# SYS_INTC register map
Vendor: Texas Instruments
Peripheral module from a debugger description file (folder omap4430).
Registers are 32-bit, read-only, reset 0x0 unless marked. A register's access mark holds for its fields unless they carry their own. Offsets are as the file gives them; lines under a group give offsets from that group; [hi:lo] are bit positions; {n}, {i} and the like mark numbered series; 'fields as' and 'values as' point back to an identical list; <NAME> marks a mode.

## SYS_INTC
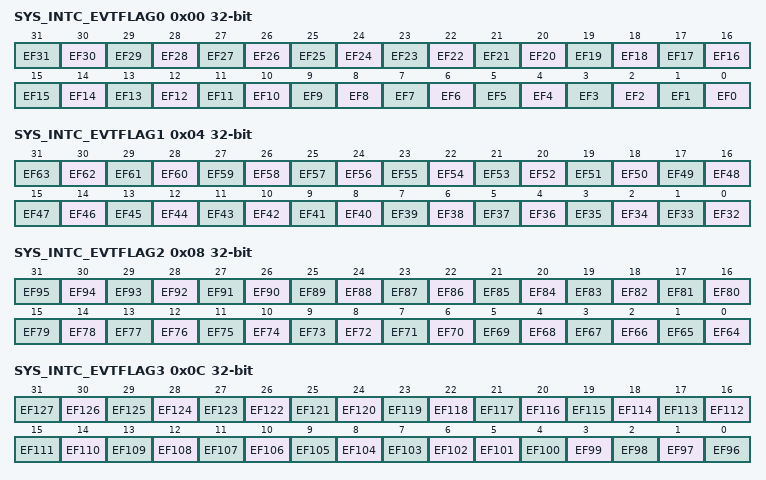
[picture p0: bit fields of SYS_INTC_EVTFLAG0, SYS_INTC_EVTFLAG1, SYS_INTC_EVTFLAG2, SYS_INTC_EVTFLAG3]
0x00 SYS_INTC_EVTFLAG0 — Event Flag Register 0
  [n] EF{n} (n=10..31) — Event Flag number {10n}: no event occurred1: an event occurred
  [n] EF{n} (n=0..9) — Event Flag number {10n:02}: no event occurred1: an event occurred
0x04 SYS_INTC_EVTFLAG1 — Event Flag Register 1
  [n-32] EF{n} (n=32..63) — Event Flag number {10n}: no event occurred1: an event occurred
0x08 SYS_INTC_EVTFLAG2 — Event Flag Register 2
  [n-64] EF{n} (n=64..95) — Event Flag number {10n}: no event occurred1: an event occurred
0x0C SYS_INTC_EVTFLAG3 — Event Flag Register 3
  [n-96] EF{n} (n=102..127) — Event Flag number {10n}: no event occurred1: an event occurred
  [5] EF101 — Event Flag number 1010: no event occurred 1: an event occurred
  [n-96] EF{n} (n=96..100) — Event Flag number {10n}: no event occurred1: an event occurred
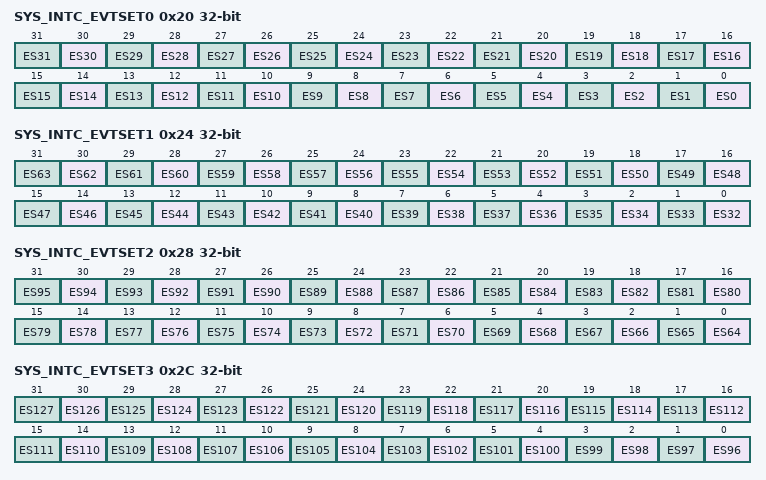
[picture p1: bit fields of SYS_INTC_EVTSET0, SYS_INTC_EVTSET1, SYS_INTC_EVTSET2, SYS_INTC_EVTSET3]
0x20 SYS_INTC_EVTSET0 wo — Event Set Register 0
  [n] ES{n} (n=0..31) — Event Set number {n}write 0: no actionwrite 1: set corresponding event flag
0x24 SYS_INTC_EVTSET1 wo — Event Set Register 1
  [n-32] ES{n} (n=32..63) — Event Set number {n}write 0: no actionwrite 1: set corresponding event flag
0x28 SYS_INTC_EVTSET2 wo — Event Set Register 2
  [n-64] ES{n} (n=64..95) — Event Set number {n}write 0: no actionwrite 1: set corresponding event flag
0x2C SYS_INTC_EVTSET3 wo — Event Set Register 3
  [n-96] ES{n} (n=96..127) — Event Set number {n}write 0: no actionwrite 1: set corresponding event flag
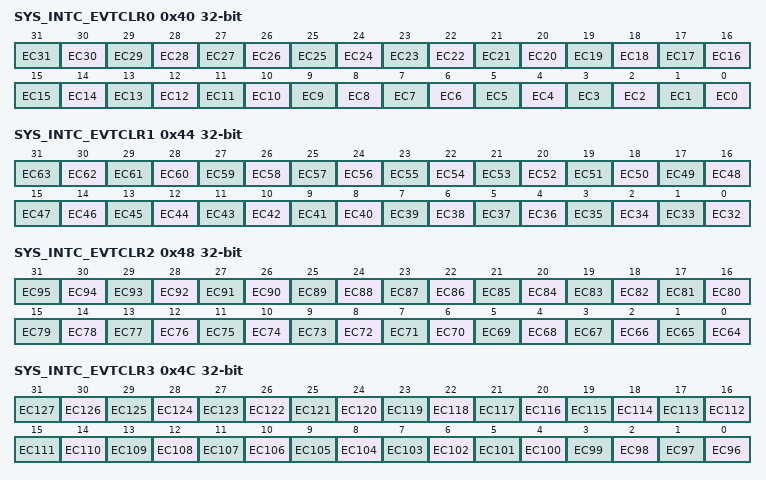
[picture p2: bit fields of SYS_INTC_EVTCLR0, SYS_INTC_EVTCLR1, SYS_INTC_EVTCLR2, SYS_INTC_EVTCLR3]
0x40 SYS_INTC_EVTCLR0 wo — Event Clear Register 0
  [n] EC{n} (n=0..31) — Event Clear number {n}write 0: no actionwrite 1: clear corresponding event
0x44 SYS_INTC_EVTCLR1 wo — Event Clear Register 1
  [n-32] EC{n} (n=32..63) — Event Clear number {n}write 0: no actionwrite 1: clear corresponding event
0x48 SYS_INTC_EVTCLR2 wo — Event Clear Register 2
  [n-64] EC{n} (n=64..95) — Event Clear number {n}write 0: no actionwrite 1: clear corresponding event
0x4C SYS_INTC_EVTCLR3 wo — Event Clear Register 3
  [n-96] EC{n} (n=96..127) — Event Clear number {n}write 0: no actionwrite 1: clear corresponding event
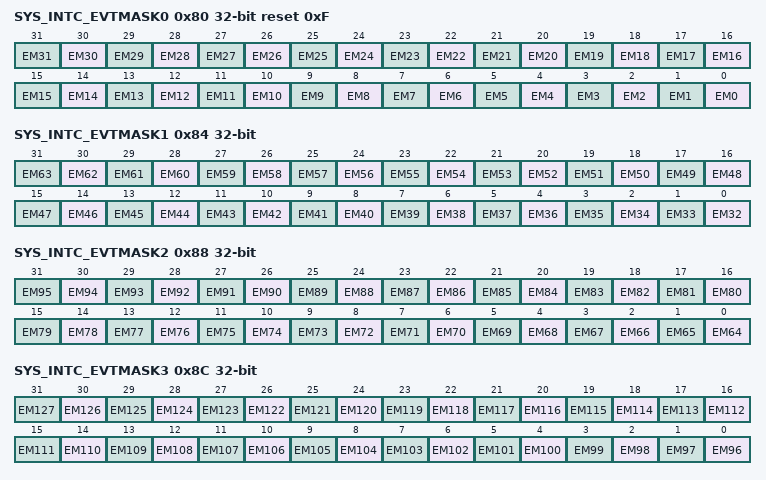
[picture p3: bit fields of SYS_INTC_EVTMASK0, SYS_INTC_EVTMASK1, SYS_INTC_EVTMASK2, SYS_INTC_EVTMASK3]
0x80 SYS_INTC_EVTMASK0 access per field reset 0xF — Event Mask Register 0
  [n] EM{n} rw (n=4..31) — Event Mask number {n}write 0: no actionwrite 1: mask corresponding event
  [n] EM{n} ro (n=0..3) — Event Mask number {n}write 0: no actionwrite 1: mask corresponding event
0x84 SYS_INTC_EVTMASK1 rw — Event Mask Register 1
  [n-32] EM{n} (n=32..63) — Event Mask number {n}write 0: no actionwrite 1: mask corresponding event
0x88 SYS_INTC_EVTMASK2 rw — Event Mask Register 2
  [n-64] EM{n} (n=64..95) — Event Mask number {n}write 0: no actionwrite 1: mask corresponding event
0x8C SYS_INTC_EVTMASK3 rw — Event Mask Register 3
  [n-96] EM{n} (n=100..127) — Event Mask number {n}write 0: no action write 1: mask corresponding event
  [n-96] EM{n} (n=96..99) — Event Mask number {n}write 0: no actionwrite 1: mask corresponding event
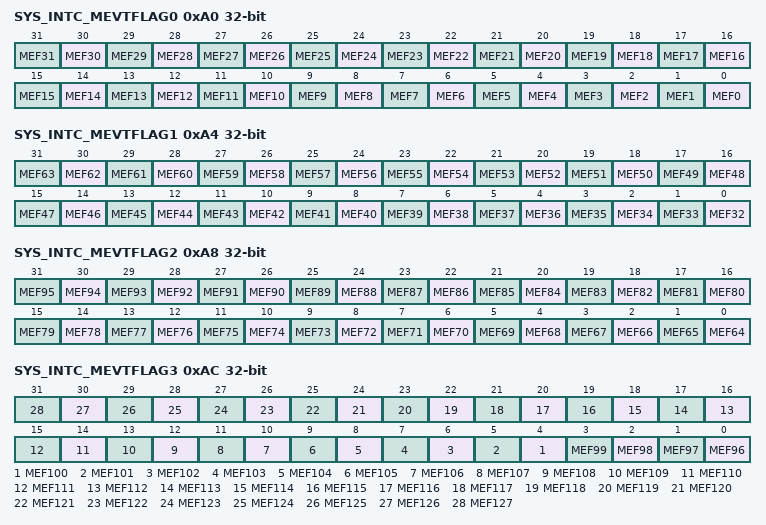
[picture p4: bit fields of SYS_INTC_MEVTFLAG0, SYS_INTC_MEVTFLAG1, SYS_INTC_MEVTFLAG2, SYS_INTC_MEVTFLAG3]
0xA0 SYS_INTC_MEVTFLAG0 — Masked Event Flag Register 0
  [n] MEF{n} (n=10..31) — Masked Event Flag number {10n}: no event occurred1: an event occurred
  [n] MEF{n} (n=0..9) — Masked Event Flag number {10n:02}: no event occurred1: an event occurred
0xA4 SYS_INTC_MEVTFLAG1 — Masked Event Flag Register 1
  [n-32] MEF{n} (n=32..63) — Masked Event Flag number {10n}: no event occurred1: an event occurred
0xA8 SYS_INTC_MEVTFLAG2 — Masked Event Flag Register 2
  [n-64] MEF{n} (n=64..95) — Masked Event Flag number {10n}: no event occurred1: an event occurred
0xAC SYS_INTC_MEVTFLAG3 — Masked Event Flag Register 3
  [n-96] MEF{n} (n=96..127) — Masked Event Flag number {10n}: no event occurred1: an event occurred
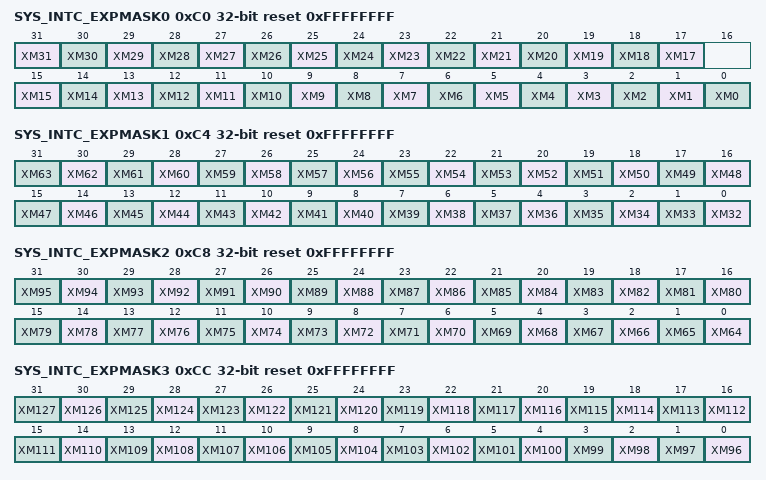
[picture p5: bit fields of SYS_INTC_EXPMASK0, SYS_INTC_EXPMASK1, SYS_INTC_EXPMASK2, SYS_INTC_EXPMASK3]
0xC0 SYS_INTC_EXPMASK0 access per field reset 0xFFFFFFFF — Exception Mask Register 0
  [n] XM{n} rw (n=17..31) — Exception Mask number {n}write 0: no action write 1: mask corresponding event
  [n] XM{n} rw (n=4..15) — Exception Mask number {n}write 0: no action write 1: mask corresponding event
  [n] XM{n} ro (n=0..3) — Exception Mask number {n}write 0: no action write 1: mask corresponding event
0xC4 SYS_INTC_EXPMASK1 rw reset 0xFFFFFFFF — Exception Mask Register 1
  [n-32] XM{n} (n=32..63) — Exception Mask number {n}write 0: no action write 1: mask corresponding event
0xC8 SYS_INTC_EXPMASK2 rw reset 0xFFFFFFFF — Exception Mask Register 2
  [n-64] XM{n} (n=64..95) — Exception Mask number {n}write 0: no action write 1: mask corresponding event
0xCC SYS_INTC_EXPMASK3 rw reset 0xFFFFFFFF — Exception Mask Register 3
  [n-96] XM{n} (n=96..127) — Exception Mask number {n}write 0: no action write 1: mask corresponding event
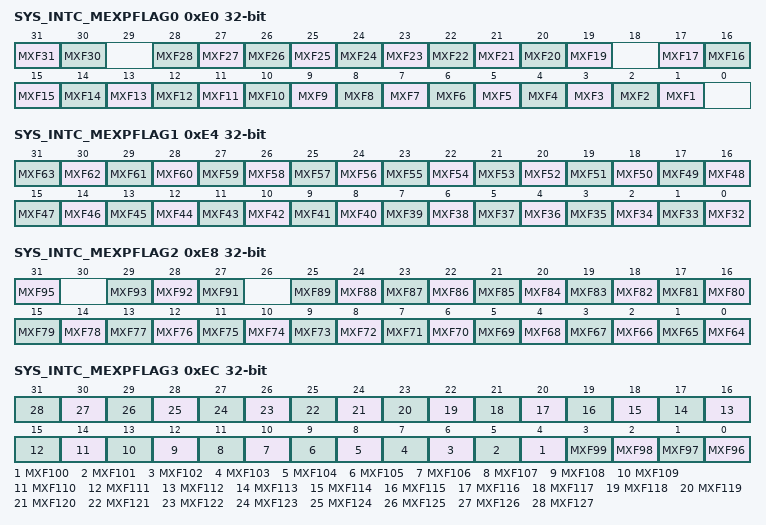
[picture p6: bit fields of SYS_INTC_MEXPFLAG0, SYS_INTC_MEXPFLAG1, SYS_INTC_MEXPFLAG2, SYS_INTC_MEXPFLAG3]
0xE0 SYS_INTC_MEXPFLAG0 — Masked Exception Flag Register 0
  [31] MXF31 — Masked Exception Flag number 310: no event occurred1: an event occurred
  [30] MXF30 — Masked Exception Flag number 300: no event occurred1: an event occurred
  [n] MXF{n} (n=19..28) — Masked Exception Flag number {10n}: no event occurred1: an event occurred
  [n] MXF{n} (n=1..17) — Masked Exception Flag number {10n}: no event occurred1: an event occurred
0xE4 SYS_INTC_MEXPFLAG1 — Masked Exception Flag Register 1
  [n-32] MXF{n} (n=32..63) — Masked Exception Flag number {10n}: no event occurred1: an event occurred
0xE8 SYS_INTC_MEXPFLAG2 — Masked Exception Flag Register 2
  [31] MXF95 — Masked Exception Flag number 950: no event occurred1: an event occurred
  [29] MXF93 — Masked Exception Flag number 930: no event occurred1: an event occurred
  [28] MXF92 — Masked Exception Flag number 920: no event occurred1: an event occurred
  [27] MXF91 — Masked Exception Flag number 910: no event occurred1: an event occurred
  [n-64] MXF{n} (n=64..89) — Masked Exception Flag number {10n}: no event occurred1: an event occurred
0xEC SYS_INTC_MEXPFLAG3 — Masked Exception Flag Register 3
  [n-96] MXF{n} (n=96..127) — Masked Exception Flag number {10n}: no event occurred1: an event occurred
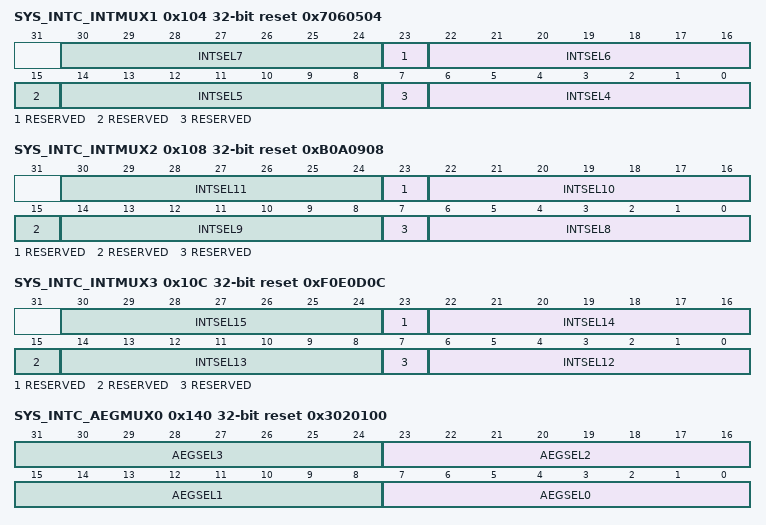
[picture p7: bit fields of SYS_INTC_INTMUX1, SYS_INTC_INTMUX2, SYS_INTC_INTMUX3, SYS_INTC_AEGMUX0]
0x104 SYS_INTC_INTMUX1 access per field reset 0x7060504 — Interrupt Mux Register 1
  [8n-26:8n-32] INTSEL{n} rw (n=4..7) — Source event number of the CPU interrupt #{n}
  [23] RESERVED rw — write 0 for further compatibility reads return 0's
  [15] RESERVED rw — write 0 for further compatibility reads return 0's
  [7] RESERVED rw — write 0 for further compatibility reads return 0's
0x108 SYS_INTC_INTMUX2 access per field reset 0xB0A0908 — Interrupt Mux Register 2
  [8n-58:8n-64] INTSEL{n} rw (n=8..11) — Source event number of the CPU interrupt #{n}
  [23] RESERVED rw — write 0 for further compatibility reads return 0's
  [15] RESERVED rw — write 0 for further compatibility reads return 0's
  [7] RESERVED rw — write 0 for further compatibility reads return 0's
0x10C SYS_INTC_INTMUX3 access per field reset 0xF0E0D0C — Interrupt Mux Register 3
  [8n-90:8n-96] INTSEL{n} rw (n=12..15) — Source event number of the CPU interrupt #{n}
  [23] RESERVED rw — write 0 for further compatibility reads return 0's
  [15] RESERVED rw — write 0 for further compatibility reads return 0's
  [7] RESERVED rw — write 0 for further compatibility reads return 0's
0x140 SYS_INTC_AEGMUX0 rw reset 0x3020100 — AEG Mux Register 0
  [8n+7:8n] AEGSEL{n} (n=0..3) — Source for Advanced Emulation Event #{n}
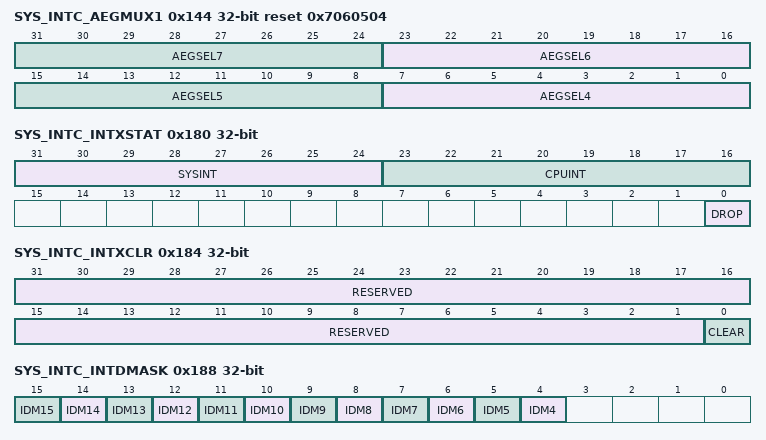
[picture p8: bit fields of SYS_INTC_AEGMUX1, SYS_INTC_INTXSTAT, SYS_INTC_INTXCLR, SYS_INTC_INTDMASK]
0x144 SYS_INTC_AEGMUX1 rw reset 0x7060504 — AEG Mux Register 1
  [8n-25:8n-32] AEGSEL{n} (n=4..7) — Source for Advanced Emulation Event #{n}
0x180 SYS_INTC_INTXSTAT — Interrupt Exception Status Register
  [31:24] SYSINT — System Event number0x0: EVT0....0x7F: EVT128others: reserved
  [23:16] CPUINT — CPU interrupt number0x0: CPUINT0... 0xF: CPUINT15others: reserved
  [0] DROP — Dropped event flag0: No events dropped1: Event was dropped by the CPU
0x184 SYS_INTC_INTXCLR wo — Interrupt Exception Clear Register
  [31:1] RESERVED — write 0 for further compatibility
  [0] CLEAR — Interrupt exception status clear register:write 0: no effect write 1: clears the Interrupt Exception Status register
0x188 SYS_INTC_INTDMASK access per field — Dropped Interrupt Mask Register
  [n] IDM{n} rw (n=4..15) — Dropped event mask for CPU interrupt #{n}
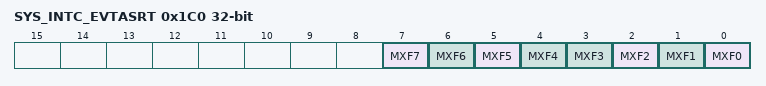
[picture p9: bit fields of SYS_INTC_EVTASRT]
0x1C0 SYS_INTC_EVTASRT access per field — Event Assert Register
  [7] MXF7 wo — Event Assert output #7EA7 = 0: No effectEA7 = 1: EVTOUT7 pulsed high for 4 clk1 cycles, then low.
  [6] MXF6 wo — Event Assert output #6EA6 = 0: No effectEA6 = 1: EVTOUT6 pulsed high for 4 clk1 cycles, then low.
  [5] MXF5 wo — Event Assert output #5EA5 = 0: No effectEA5 = 1: EVTOUT5 pulsed high for 4 clk1 cycles, then low.
  [4] MXF4 wo — Event Assert output #4EA4 = 0: No effec EA4 = 1: EVTOUT4 pulsed high for 4 clk1 cycles, then low.
  [n] MXF{n} wo (n=0..3) — Event Assert output #{n}EA{n} = 0: No effectEA{n} = 1: EVTOUT{n} pulsed high for 4 clk1 cycles, then low.
